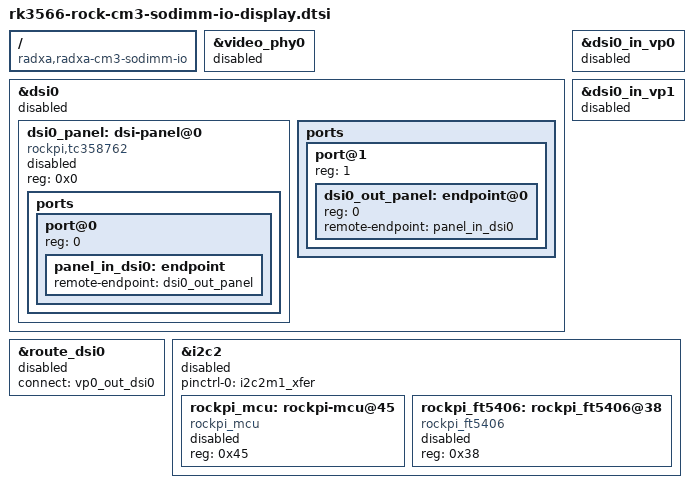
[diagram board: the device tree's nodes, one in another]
// SPDX-License-Identifier: (GPL-2.0+ OR MIT)
/*
 * Copyright (c) 2022 Radxa Limited.
 *
 */

/ {
	compatible = "radxa,radxa-cm3-sodimm-io", "rockchip,rk3566";
};

&video_phy0 {
    status = "disabled";
};

&dsi0 {
	status = "disabled";

	dsi0_panel: dsi-panel@0 {
		compatible = "rockpi,tc358762";
		reg = <0x0>;
		status = "disabled";

		ports {
			#address-cells = <1>;
			#size-cells = <0>;

			port@0 {
				reg = <0>;

				panel_in_dsi0: endpoint {
					remote-endpoint = <&dsi0_out_panel>;
				};
			};
		};
	};

	ports {
		#address-cells = <1>;
		#size-cells = <0>;

		port@1 {
			reg = <1>;
			#address-cells = <1>;
			#size-cells = <0>;

			dsi0_out_panel: endpoint@0 {
				reg = <0>;
				remote-endpoint = <&panel_in_dsi0>;
			};
		};
	};
};

&dsi0_in_vp0 {
	status = "disabled";
};

&dsi0_in_vp1 {
	status = "disabled";
};

&route_dsi0 {
	status = "disabled";
	connect = <&vp0_out_dsi0>;
};

&i2c2 {
	status = "disabled";
	pinctrl-0 = <&i2c2m1_xfer>;

	rockpi_mcu: rockpi-mcu@45 {
		compatible = "rockpi_mcu";
		reg = <0x45>;
		status = "disabled";
	};

	rockpi_ft5406: rockpi_ft5406@38 {
		compatible = "rockpi_ft5406";
		reg = <0x38>;
		status = "disabled";
	};
};
